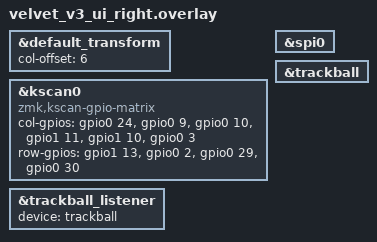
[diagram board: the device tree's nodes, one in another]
#include "velvet_v3_ui.dtsi"

&default_transform {
    col-offset = <6>;
};

&kscan0 {
    compatible = "zmk,kscan-gpio-matrix";

    col-gpios
        = <&gpio0 24 GPIO_ACTIVE_HIGH>
        , <&gpio0 9 GPIO_ACTIVE_HIGH>
        , <&gpio0 10 GPIO_ACTIVE_HIGH>
        , <&gpio1 11 GPIO_ACTIVE_HIGH>
        , <&gpio1 10 GPIO_ACTIVE_HIGH>
        , <&gpio0 3 GPIO_ACTIVE_HIGH>
        ;

    row-gpios
        = <&gpio1 13 (GPIO_ACTIVE_HIGH | GPIO_PULL_DOWN)>
        , <&gpio0 2 (GPIO_ACTIVE_HIGH | GPIO_PULL_DOWN)>
        , <&gpio0 29 (GPIO_ACTIVE_HIGH | GPIO_PULL_DOWN)>
        , <&gpio0 30 (GPIO_ACTIVE_HIGH | GPIO_PULL_DOWN)>
        ;
};

&spi0 {
    status = "okay";
};

&trackball {
    status = "okay";
};

&trackball_listener {
    status = "okay";
    device = <&trackball>;
};
